VERSION "ROS_Teleop_Control_Only_160_161_v1"

NS_ :

BS_:

BU_: Pi DUE

CM_ "DBC with only control command/feedback frames (0xA1 / 0xA0).";

# -----------------------------
# Messages & Signals
# -----------------------------

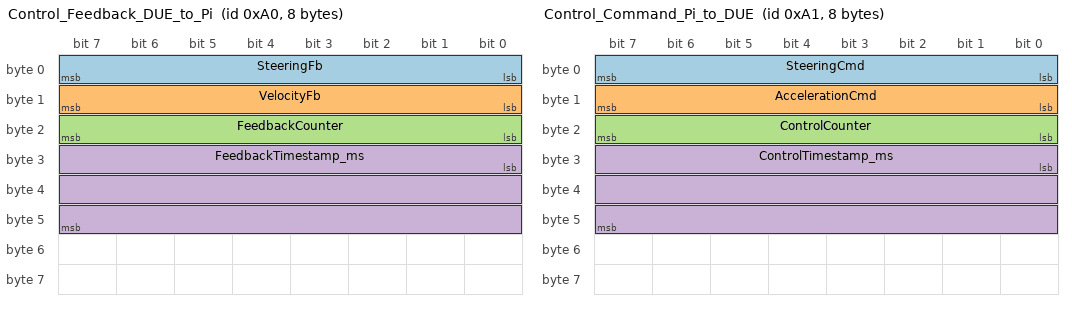
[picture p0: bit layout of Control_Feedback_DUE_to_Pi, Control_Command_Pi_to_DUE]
BO_ 160 Control_Feedback_DUE_to_Pi: 8 VehicleBus
 SG_ SteeringFb          : 0|8@1-   (1,0)   [-128|127]     ""  Pi
 SG_ VelocityFb          : 8|8@1-   (1,0)   [-128|127]     ""  Pi
 SG_ FeedbackCounter       : 16|8@1+  (1,0)   [0|255]        ""  Pi
 SG_ FeedbackTimestamp_ms  : 24|24@1+ (1,0)   [0|16777215]   "ms" Pi
CM_ BO_ 160 "DUE -> Pi control feedback @100Hz";

BO_ 161 Control_Command_Pi_to_DUE: 8 VehicleBus
 SG_ SteeringCmd           : 0|8@1+   (1,0)   [0|255]        ""  DUE
 SG_ AccelerationCmd       : 8|8@1+   (1,0)   [0|255]        ""  DUE
 SG_ ControlCounter      : 16|8@1+  (1,0)   [0|255]        ""  DUE
 SG_ ControlTimestamp_ms : 24|24@1+ (1,0)   [0|16777215]   "ms" DUE
CM_ BO_ 161 "Pi -> DUE control commands @100Hz";

# -----------------------------
# Transmitters
# -----------------------------
BO_TX_BU_ 160 : DUE;
BO_TX_BU_ 161 : PI;

# -----------------------------
# Attributes
# -----------------------------
BA_DEF_  "GenMsgCycleTime" INT 0 65535;
BA_DEF_  "BusType" STRING;

BA_ "GenMsgCycleTime" BO_ 160 10;
BA_ "GenMsgCycleTime" BO_ 161 10;

BA_ "BusType" BO_ 160 "CAN";
BA_ "BusType" BO_ 161 "CAN";

# -----------------------------
# Value Descriptions (VAL_)
# -----------------------------

# Feedback frame (ID 160)
VAL_ 160 SteeringFb            -128 "STEER_LEFT_MAX" 0 "STEER_CENTER" 127 "STEER_RIGHT_MAX" ;
VAL_ 160 VelocityFb            -128 "VEL_REV_MAX"    0 "VEL_STOP"     127 "VEL_FWD_MAX" ;
VAL_ 160 FeedbackCounter       255 "SNA" 0 "INIT" ;
VAL_ 160 FeedbackTimestamp_ms  16777215 "SNA" ;

# Command frame (ID 161)
VAL_ 161 SteeringCmd           0 "STEER_MIN"   255 "STEER_MAX" ;
VAL_ 161 AccelerationCmd       0 "ACCEL_MIN"   255 "ACCEL_MAX" ;
VAL_ 161 ControlCounter      255 "SNA" 0 "INIT" ;
VAL_ 161 ControlTimestamp_ms 16777215 "SNA" ;
